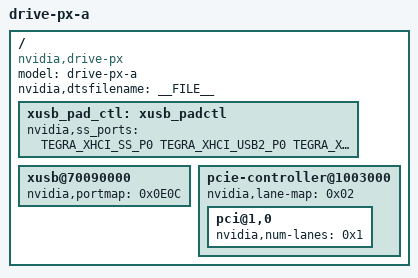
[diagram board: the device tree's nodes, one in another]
/*
 * T210- VCM3.1 E2379-B00 Drive-PX
 *
 * arch/arm64/boot/dts/tegra210-vcm31-e2379-0000-b00-00-a.dts
 *
 * Copyright (c) 2015, NVIDIA CORPORATION.  All rights reserved.
 *
 * This program is free software; you can redistribute it and/or modify
 * it under the terms of the GNU General Public License as published by
 * the Free Software Foundation; version 2 of the License.
 *
 * This program is distributed in the hope that it will be useful, but WITHOUT
 * ANY WARRANTY; without even the implied warranty of MERCHANTABILITY or
 * FITNESS FOR A PARTICULAR PURPOSE.  See the GNU General Public License for
 * more details.
 *
 * You should have received a copy of the GNU General Public License along
 * with this program; if not, write to the Free Software Foundation, Inc.,
 * 51 Franklin Street, Fifth Floor, Boston, MA  02110-1301, USA.
 *
 */

#include "tegra210-vcm31-e2379-b00-common.dtsi"

/ {
	model = "drive-px-a";
	compatible = "nvidia,drive-px", "nvidia,tegra210";
	nvidia,dtsfilename = __FILE__;

	xusb_pad_ctl: xusb_padctl {
		/*
		 *ss_portmap
		 *SSP3 -> USB2P2 -> USB_C (0x2...)
		 *SSP2 -> USB2P3 -> USB_D (0x.3..)
		 *SSP1 not routed through any lanes (0x..7.)
		 *SSP0 not routed through any lanes (0x...7)
		 */

		/*
		 *lane_owner
		 *SSP3 -> PEX lane 4 -> T210S01: PEX_USB3_L1 (0x4...)
		 *SSP2 -> PEX lane 0 -> T210S01: PEX_USB3_L0 (0x.0..)
		 *SSP1 and 0 not routed through any lanes  (0x..FF)
		 */
		nvidia,ss_ports = <TEGRA_XHCI_SS_P0 TEGRA_XHCI_USB2_P0 TEGRA_XHCI_UNUSED_LANE TEGRA_XHCI_PORT_OTG
				   TEGRA_XHCI_SS_P1 TEGRA_XHCI_UNUSED_PORT TEGRA_XHCI_UNUSED_LANE TEGRA_XHCI_PORT_STD
				   TEGRA_XHCI_SS_P2 TEGRA_XHCI_USB2_P3 TEGRA_XHCI_LANE_0 TEGRA_XHCI_PORT_STD
				   TEGRA_XHCI_SS_P3 TEGRA_XHCI_USB2_P2 TEGRA_XHCI_LANE_4 TEGRA_XHCI_PORT_STD>;
		status = "okay";
	};

	xusb@70090000 {
		nvidia,portmap = <0x0E0C>;
		status = "okay";
	};

	pcie-controller@1003000 {
		status = "okay";
		/*
		 *lane_map (Lane Width)
		 *PEX1 : not used (L0 is connected with SSP2)
		 *PEX0 (max width 2)
		 */
		nvidia,lane-map = <0x02>;
		pci@1,0 {
			status = "okay";
			/* T210S01: PEX0 <-> FPGA (X1) */
			nvidia,num-lanes = <0x1>;
		};
	};
};
